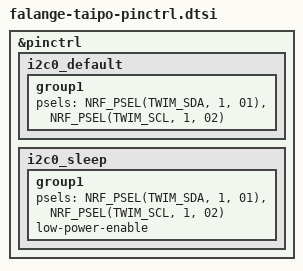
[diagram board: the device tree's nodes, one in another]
&pinctrl {
    i2c0_default: i2c0_default {
        group1 {
            psels = <NRF_PSEL(TWIM_SDA, 1, 01)>,
                <NRF_PSEL(TWIM_SCL, 1, 02)>;
        };
    };

    i2c0_sleep: i2c0_sleep {
        group1 {
            psels = <NRF_PSEL(TWIM_SDA, 1, 01)>,
                <NRF_PSEL(TWIM_SCL, 1, 02)>;
            low-power-enable;
        };
    };
};
